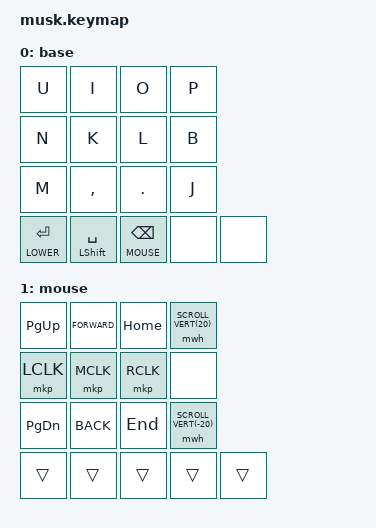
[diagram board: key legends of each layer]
/*
 * Copyright (c) 2020 The ZMK Contributors
 *
 * SPDX-License-Identifier: MIT
 */

#include <behaviors.dtsi>
#include <dt-bindings/zmk/keys.h>
#include <dt-bindings/zmk/bt.h>
#include <dt-bindings/zmk/outputs.h>
#include <dt-bindings/zmk/mouse.h>

&mwh { status = "okay"; };

/ {
    behaviors {
        // My Modtap
        mm: behavior_mod_tap {
            compatible = "zmk,behavior-hold-tap";
            label = "MOD_TAP";
            #binding-cells = <2>;
            flavor = "balanced";
            tapping-term-ms = <150>;
            bindings = <&kp>, <&kp>;
        };
        // My Layertap
        ml: behavior_layer_tap {
            compatible = "zmk,behavior-hold-tap";
            label = "LAYER_TAP";
            #binding-cells = <2>;
            flavor = "hold-preferred";
            tapping-term-ms = <150>;
            bindings = <&mo>, <&kp>;
        };
        qt: behavior_layer_tap {
            compatible = "zmk,behavior-hold-tap";
            label = "quick tap";
            #binding-cells = <2>;
            flavor = "hold-preferred";
            tapping-term-ms = <150>;
            quick-tap-ms = <250>;
            bindings = <&mo>, <&kp>;
        };
    };
    /* combos { */
    /*     compatible = "zmk,combos"; */
/* #define CONCAT2(x, y) x ## y */
/* #define CONCAT(x, y) CONCAT2(x, y) */
/* #define COMBO(pos, k) CONCAT(combo, __COUNTER__) { key-positions = <pos>; bindings = <&kp k>; layers = <0 1 2 3 4>; timeout-ms = <60>; }; */
    /* }; */
#define BASE  0
#define MOUSE 1
#define LOWER 2
#define RAISE 3

    keymap0: keymap {
        compatible = "zmk,keymap";
        base {
            bindings = <
&kp U         &kp I         &kp O          &kp P
&kp N         &kp K         &kp L          &kp B
&kp M         &kp COMMA     &kp DOT        &kp J
&ml LOWER RET &mm LSHFT SPC &qt MOUSE BSPC &none                 &none
            >;
            sensor-bindings = <&mwh SCROLL_VERT(-100)>, <&mwh SCROLL_VERT(100)>;
        };
        mouse {
            bindings = <
&kp PG_UP &kp K_FORWARD &kp HOME  &mwh SCROLL_VERT(20)
&mkp LCLK &mkp MCLK     &mkp RCLK &none
&kp PG_DN &kp K_BACK    &kp END   &mwh SCROLL_VERT(-20)
&trans    &trans        &trans    &trans                 &trans
            >;
            sensor-bindings = <&mwh SCROLL_VERT(-100)>, <&mwh SCROLL_VERT(100)>;
        };
    };
};
